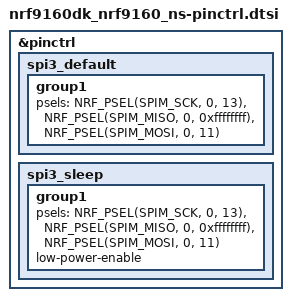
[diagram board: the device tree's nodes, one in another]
&pinctrl {
	spi3_default: spi3_default {
		group1 {
			psels = <NRF_PSEL(SPIM_SCK, 0, 13)>,
				<NRF_PSEL(SPIM_MISO, 0, 0xffffffff)>,
				<NRF_PSEL(SPIM_MOSI, 0, 11)>;
		};
	};

	spi3_sleep: spi3_sleep {
		group1 {
			psels = <NRF_PSEL(SPIM_SCK, 0, 13)>,
				<NRF_PSEL(SPIM_MISO, 0, 0xffffffff)>,
				<NRF_PSEL(SPIM_MOSI, 0, 11)>;
			low-power-enable;
		};
	};
};
